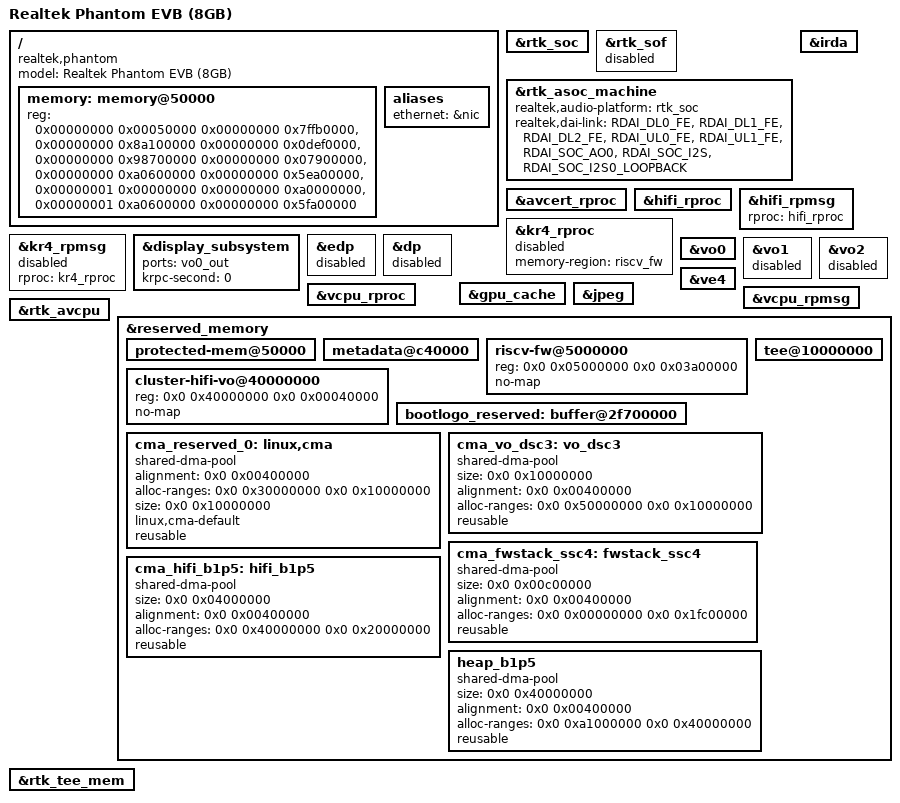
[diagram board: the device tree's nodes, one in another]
// SPDX-License-Identifier: (GPL-2.0-or-later OR BSD-2-Clause)
/*
 * Realtek RTD1501S Phantom EVB
 *
 * Copyright (c) 2024 Realtek Semiconductor Corp.
 */

/dts-v1/;

#include "rtd1501s-phantom.dtsi"

/ {
	compatible = "realtek,phantom", "realtek,rtd1501s";
	model = "Realtek Phantom EVB (8GB)";

	memory: memory@50000 {
		device_type = "memory";
		reg = <0x00000000 0x00050000 0x00000000 0x7ffb0000>,
		      <0x00000000 0x8a100000 0x00000000 0x0def0000>,
		      <0x00000000 0x98700000 0x00000000 0x07900000>,
		      <0x00000000 0xa0600000 0x00000000 0x5ea00000>,
		      <0x00000001 0x00000000 0x00000000 0xa0000000>,
		      <0x00000001 0xa0600000 0x00000000 0x5fa00000>;
	};

	aliases {
		ethernet = &nic;
	};
};

&rtk_soc {
	status = "okay";
};

&rtk_sof {
	status = "disabled";
};

&rtk_asoc_machine {
	pinctrl-names = "default";
	realtek,audio-platform = <&rtk_soc>;
	realtek,dai-link = "RDAI_DL0_FE", "RDAI_DL1_FE", "RDAI_DL2_FE",
			   "RDAI_UL0_FE", "RDAI_UL1_FE",
			   "RDAI_SOC_AO0", "RDAI_SOC_I2S", "RDAI_SOC_I2S0_LOOPBACK";
	status = "okay";
};

&irda {
	status = "okay";
};

&avcert_rproc {
	status = "okay";
};

&hifi_rproc {
	/delete-property/ is-booted;
	/delete-property/ need-ext-fw;
	status = "okay";
};

&hifi_rpmsg {
	/delete-property/ skip-handshake;
	rproc = <&hifi_rproc>;
	status = "okay";
};

&kr4_rproc {
	memory-region = <&riscv_fw>;
	status = "disabled";
};

&kr4_rpmsg {
	rproc = <&kr4_rproc>;
	status = "disabled";
};

&display_subsystem {
	status = "okay";
	ports = <&vo0_out>;
	krpc-second = <0>;
};

&edp {
	status = "disabled";
};

&dp {
	status = "disabled";
};

&vo0 {
	status = "okay";
};

&vo1 {
	status = "disabled";
};

&vo2 {
	status = "disabled";
};

&gpu_cache {
    status = "okay";
};

&ve4  {
        status = "okay";
};

&jpeg {
    status = "okay";
};

&vcpu_rproc {
    status = "okay";
};

&vcpu_rpmsg {
    status = "okay";
};

&rtk_avcpu {
    status = "okay";
};

&reserved_memory {
	protected-mem@50000 {
		status = "okay";
	};

	metadata@c40000 {
		status = "okay";
	};

	riscv-fw@5000000 {
		reg = <0x0 0x05000000 0x0 0x03a00000>;  /* riscv FW 58MB */
		no-map;
	};

	cluster-hifi-vo@40000000 {
		reg = <0x0 0x40000000 0x0 0x00040000>;  /* Cluster to Hifi vo 256kb */
		no-map;
	};

	tee@10000000 {
		status = "okay";
	};

	bootlogo_reserved: buffer@2f700000 {
		status = "okay";
	};

    cma_reserved_0:linux,cma {
        compatible = "shared-dma-pool";
        alignment = <0x0 0x00400000>;
        /* Avoid crossing A/VCPU PA2VA per 512M boundary */
        /* Avoid allocating 0x1fc00000 ~ 0x1fc00fff to LX CPU (A/VCPU/VE3) */
        alloc-ranges=<0x0 0x30000000 0x0 0x10000000>;
        size = <0x0 0x10000000>; /* 512M */
        linux,cma-default;
        reusable;
    };

	cma_vo_dsc3:vo_dsc3 {
		compatible = "shared-dma-pool";
		size = <0x0 0x10000000>;		    /* 256M */
		alignment = <0x0 0x00400000>;

		/* Avoid crossing A/VCPU PA2VA per 512M boundary */
		/* Avoid allocating 0x1fc00000 ~ 0x1fc00fff to LX CPU (A/VCPU/VE3) */
		alloc-ranges=<0x0 0x50000000 0x0 0x10000000>;
		reusable;
	};

	cma_fwstack_ssc4:fwstack_ssc4 {
		compatible = "shared-dma-pool";
		size = <0x0 0x00c00000>;		    /* 12M */
		alignment = <0x0 0x00400000>;

		/* Avoid crossing A/VCPU PA2VA per 512M boundary */
		/* Avoid allocating 0x1fc00000 ~ 0x1fc00fff to LX CPU (A/VCPU/VE3) */
		alloc-ranges=<0x0 0x00000000 0x0 0x1fc00000>;
		reusable;
	};

	cma_hifi_b1p5:hifi_b1p5 {
		compatible = "shared-dma-pool";
		size = <0x0 0x04000000>;		    /* 64M */
		alignment = <0x0 0x00400000>;
		alloc-ranges=<0x0 0x40000000 0x0 0x20000000>;
		reusable;
	};

	heap_b1p5: heap_b1p5 {
		compatible = "shared-dma-pool";
		size = <0x0 0x40000000>;            /* 1024M */
		alignment = <0x0 0x00400000>;
		alloc-ranges = <0x0 0xa1000000 0x0 0x40000000>;
		reusable;
	};

	/delete-node/linux,cma_1;
	/delete-node/linux,cma_2;
	/delete-node/bl31-mem@10001000;
};

&rtk_tee_mem {
	status = "okay";
};
